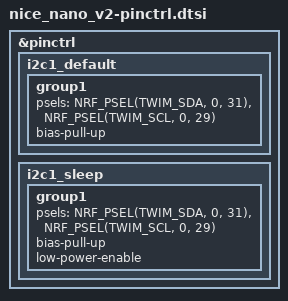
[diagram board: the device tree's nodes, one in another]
&pinctrl {
    status = "okay";
    i2c1_default: i2c1_default {
        group1 {
            psels = <NRF_PSEL(TWIM_SDA, 0, 31)>,
                    <NRF_PSEL(TWIM_SCL, 0, 29)>;
            bias-pull-up;
        };
    };

    i2c1_sleep: i2c1_sleep {
        group1 {
            psels = <NRF_PSEL(TWIM_SDA, 0, 31)>,
                    <NRF_PSEL(TWIM_SCL, 0, 29)>;
            bias-pull-up;
            low-power-enable;
        };
    };
};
